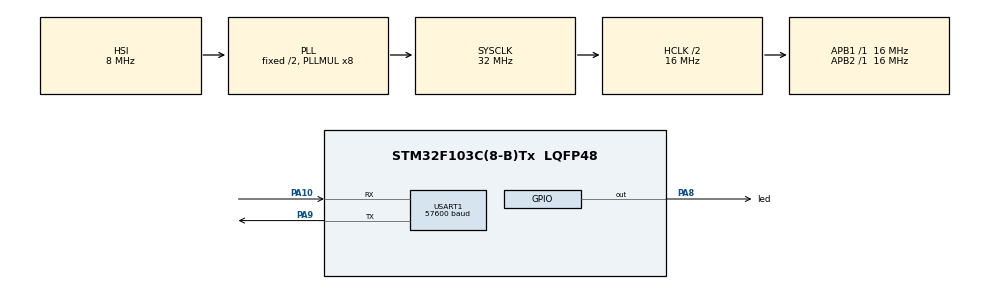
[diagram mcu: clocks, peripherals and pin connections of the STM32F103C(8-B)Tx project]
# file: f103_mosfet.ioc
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Mcu.Family=STM32F1
Dma.USART1_TX.0.MemInc=DMA_MINC_ENABLE
PD1-OSC_OUT.Mode=HSE-External-Clock-Source
Dma.USART1_TX.0.PeriphInc=DMA_PINC_DISABLE
PA10.Mode=Asynchronous
USART1.BaudRate=57600
NVIC.TIM1_UP_IRQn=true\:0\:0\:false\:false\:true\:true\:true
PD0-OSC_IN.Signal=RCC_OSC_IN
RCC.SYSCLKSource=RCC_SYSCLKSOURCE_PLLCLK
ProjectManager.StackSize=0x400
PD1-OSC_OUT.Signal=RCC_OSC_OUT
PA13.Signal=SYS_JTMS-SWDIO
PA9.Mode=Asynchronous
Dma.USART1_TX.0.Priority=DMA_PRIORITY_LOW
PA8.GPIO_Label=led
TIM1.Prescaler=1599
Dma.USART1_TX.0.Direction=DMA_MEMORY_TO_PERIPH
ProjectManager.TargetToolchain=STM32CubeIDE
RCC.HCLKFreq_Value=16000000
RCC.APB2TimFreq_Value=16000000
PA9.Signal=USART1_TX
RCC.USBFreq_Value=32000000
RCC.AHBFreq_Value=16000000
PD0-OSC_IN.Mode=HSE-External-Clock-Source
Dma.USART1_TX.0.Mode=DMA_NORMAL
board=custom
RCC.PLLMUL=RCC_PLL_MUL8
RCC.APB2Freq_Value=16000000
PA14.Mode=Serial_Wire
PA8.Signal=GPIO_Output
RCC.AHBCLKDivider=RCC_SYSCLK_DIV2
PA13.Mode=Serial_Wire
Dma.USART1_TX.0.PeriphDataAlignment=DMA_PDATAALIGN_BYTE
Mcu.Name=STM32F103C(8-B)Tx
VP_TIM1_VS_ClockSourceINT.Mode=Internal
RCC.SYSCLKFreq_VALUE=32000000
Mcu.Package=LQFP48
USART1.VirtualMode=VM_ASYNC
Dma.USART1_TX.0.MemDataAlignment=DMA_MDATAALIGN_BYTE
PA10.Signal=USART1_RX
PA14.Signal=SYS_JTCK-SWCLK
ProjectManager.HeapSize=0x200
Dma.USART1_TX.0.Instance=DMA1_Channel4
NVIC.PriorityGroup=NVIC_PRIORITYGROUP_4
RCC.APB1TimFreq_Value=16000000
TIM1.Period=9999
NVIC.DMA1_Channel4_IRQn=true\:0\:0\:false\:false\:true\:false\:true
NVIC.USART1_IRQn=true\:0\:0\:false\:false\:true\:true\:true
Dma.Request0=USART1_TX
RCC.APB1Freq_Value=16000000

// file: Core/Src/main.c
/* USER CODE BEGIN Header */
/**
  ******************************************************************************
  * @file           : main.c
  * @brief          : Main program body
  ******************************************************************************
  * @attention
  *
  * <h2><center>&copy; Copyright (c) 2021 STMicroelectronics.
  * All rights reserved.</center></h2>
  *
  * This software component is licensed by ST under BSD 3-Clause license,
  * the "License"; You may not use this file except in compliance with the
  * License. You may obtain a copy of the License at:
  *                        opensource.org/licenses/BSD-3-Clause
  *
  ******************************************************************************
  */
/* USER CODE END Header */
#include "main.h"

/* USER CODE BEGIN Includes */
#include "stdio.h"
#include "string.h"
/* USER CODE END Includes */

/* USER CODE BEGIN PD */
#define msg_SIZE 60
/* USER CODE END PD */

TIM_HandleTypeDef htim1;

UART_HandleTypeDef huart1;
DMA_HandleTypeDef hdma_usart1_tx;

/* USER CODE BEGIN PV */
static char UART_msg_TX[msg_SIZE]; // массив для формирования сообщений для вывода по UART
uint8_t flag = 1;
/* USER CODE END PV */

void SystemClock_Config(void);
static void MX_GPIO_Init(void);
static void MX_DMA_Init(void);
static void MX_TIM1_Init(void);
static void MX_USART1_UART_Init(void);

/* USER CODE BEGIN 0 */
//прерывание 1 раз в 10 мс
void HAL_TIM_PeriodElapsedCallback(TIM_HandleTypeDef *htim)
{
        if(htim->Instance == TIM1) //check if the interrupt comes from TIM2
        {
        	if (flag)
        	{
        		HAL_GPIO_WritePin(led_GPIO_Port, led_Pin, ENABLE);
        		sprintf (UART_msg_TX,"mosfet_open\r\n");
        		HAL_UART_Transmit_DMA(&huart1, (uint8_t*)UART_msg_TX, strlen(UART_msg_TX));
        		flag = 0;
        	}
        	else
        	{
        		HAL_GPIO_WritePin(led_GPIO_Port, led_Pin, DISABLE);
        		sprintf (UART_msg_TX,"mosfet_close\r\n");
        		HAL_UART_Transmit_DMA(&huart1, (uint8_t*)UART_msg_TX, strlen(UART_msg_TX));
        		flag = 1;
        	}
        }
 }

void HAL_UART_TxCpltCallback(UART_HandleTypeDef *huart)
{
          if(huart == &huart1)
          {

          }
}

/* USER CODE END 0 */

int main(void)
{

  /* MCU Configuration--------------------------------------------------------*/

  /* Reset of all peripherals, Initializes the Flash interface and the Systick. */
  HAL_Init();

  /* Configure the system clock */
  SystemClock_Config();

  /* Initialize all configured peripherals */
  MX_GPIO_Init();
  MX_DMA_Init();
  MX_TIM1_Init();
  MX_USART1_UART_Init();
  /* USER CODE BEGIN 2 */
  sprintf (UART_msg_TX,"mosfet_start\r\n");
  HAL_UART_Transmit_DMA(&huart1, (uint8_t*)UART_msg_TX, strlen(UART_msg_TX));
  HAL_Delay (500);
  HAL_TIM_Base_Start_IT (&htim1);
  /* USER CODE END 2 */

  /* Infinite loop */
  while (1)
  {

  }
}

void SystemClock_Config(void)
{
  RCC_OscInitTypeDef RCC_OscInitStruct = {0};
  RCC_ClkInitTypeDef RCC_ClkInitStruct = {0};

  /** Initializes the RCC Oscillators according to the specified parameters
  * in the RCC_OscInitTypeDef structure.
  */
  RCC_OscInitStruct.OscillatorType = RCC_OSCILLATORTYPE_HSI;
  RCC_OscInitStruct.HSIState = RCC_HSI_ON;
  RCC_OscInitStruct.HSICalibrationValue = RCC_HSICALIBRATION_DEFAULT;
  RCC_OscInitStruct.PLL.PLLState = RCC_PLL_ON;
  RCC_OscInitStruct.PLL.PLLSource = RCC_PLLSOURCE_HSI_DIV2;
  RCC_OscInitStruct.PLL.PLLMUL = RCC_PLL_MUL8;
  if (HAL_RCC_OscConfig(&RCC_OscInitStruct) != HAL_OK)
  {
    Error_Handler();
  }
  /** Initializes the CPU, AHB and APB buses clocks
  */
  RCC_ClkInitStruct.ClockType = RCC_CLOCKTYPE_HCLK|RCC_CLOCKTYPE_SYSCLK
                              |RCC_CLOCKTYPE_PCLK1|RCC_CLOCKTYPE_PCLK2;
  RCC_ClkInitStruct.SYSCLKSource = RCC_SYSCLKSOURCE_PLLCLK;
  RCC_ClkInitStruct.AHBCLKDivider = RCC_SYSCLK_DIV2;
  RCC_ClkInitStruct.APB1CLKDivider = RCC_HCLK_DIV1;
  RCC_ClkInitStruct.APB2CLKDivider = RCC_HCLK_DIV1;

  if (HAL_RCC_ClockConfig(&RCC_ClkInitStruct, FLASH_LATENCY_1) != HAL_OK)
  {
    Error_Handler();
  }
}

static void MX_TIM1_Init(void)
{

  TIM_ClockConfigTypeDef sClockSourceConfig = {0};
  TIM_MasterConfigTypeDef sMasterConfig = {0};

  htim1.Instance = TIM1;
  htim1.Init.Prescaler = 1599;
  htim1.Init.CounterMode = TIM_COUNTERMODE_UP;
  htim1.Init.Period = 9999;
  htim1.Init.ClockDivision = TIM_CLOCKDIVISION_DIV1;
  htim1.Init.RepetitionCounter = 0;
  htim1.Init.AutoReloadPreload = TIM_AUTORELOAD_PRELOAD_DISABLE;
  if (HAL_TIM_Base_Init(&htim1) != HAL_OK)
  {
    Error_Handler();
  }
  sClockSourceConfig.ClockSource = TIM_CLOCKSOURCE_INTERNAL;
  if (HAL_TIM_ConfigClockSource(&htim1, &sClockSourceConfig) != HAL_OK)
  {
    Error_Handler();
  }
  sMasterConfig.MasterOutputTrigger = TIM_TRGO_RESET;
  sMasterConfig.MasterSlaveMode = TIM_MASTERSLAVEMODE_DISABLE;
  if (HAL_TIMEx_MasterConfigSynchronization(&htim1, &sMasterConfig) != HAL_OK)
  {
    Error_Handler();
  }

}

static void MX_USART1_UART_Init(void)
{

  huart1.Instance = USART1;
  huart1.Init.BaudRate = 57600;
  huart1.Init.WordLength = UART_WORDLENGTH_8B;
  huart1.Init.StopBits = UART_STOPBITS_1;
  huart1.Init.Parity = UART_PARITY_NONE;
  huart1.Init.Mode = UART_MODE_TX_RX;
  huart1.Init.HwFlowCtl = UART_HWCONTROL_NONE;
  huart1.Init.OverSampling = UART_OVERSAMPLING_16;
  if (HAL_UART_Init(&huart1) != HAL_OK)
  {
    Error_Handler();
  }

}

static void MX_DMA_Init(void)
{

  /* DMA controller clock enable */
  __HAL_RCC_DMA1_CLK_ENABLE();

  /* DMA interrupt init */
  /* DMA1_Channel4_IRQn interrupt configuration */
  HAL_NVIC_SetPriority(DMA1_Channel4_IRQn, 0, 0);
  HAL_NVIC_EnableIRQ(DMA1_Channel4_IRQn);

}

static void MX_GPIO_Init(void)
{
  GPIO_InitTypeDef GPIO_InitStruct = {0};

  /* GPIO Ports Clock Enable */
  __HAL_RCC_GPIOD_CLK_ENABLE();
  __HAL_RCC_GPIOA_CLK_ENABLE();

  /*Configure GPIO pin Output Level */
  HAL_GPIO_WritePin(led_GPIO_Port, led_Pin, GPIO_PIN_RESET);

  /*Configure GPIO pin : led_Pin */
  GPIO_InitStruct.Pin = led_Pin;
  GPIO_InitStruct.Mode = GPIO_MODE_OUTPUT_PP;
  GPIO_InitStruct.Pull = GPIO_NOPULL;
  GPIO_InitStruct.Speed = GPIO_SPEED_FREQ_LOW;
  HAL_GPIO_Init(led_GPIO_Port, &GPIO_InitStruct);

}

void Error_Handler(void)
{
  __disable_irq();
  while (1)
  {
  }
}

/************************ (C) COPYRIGHT STMicroelectronics *****END OF FILE****/
